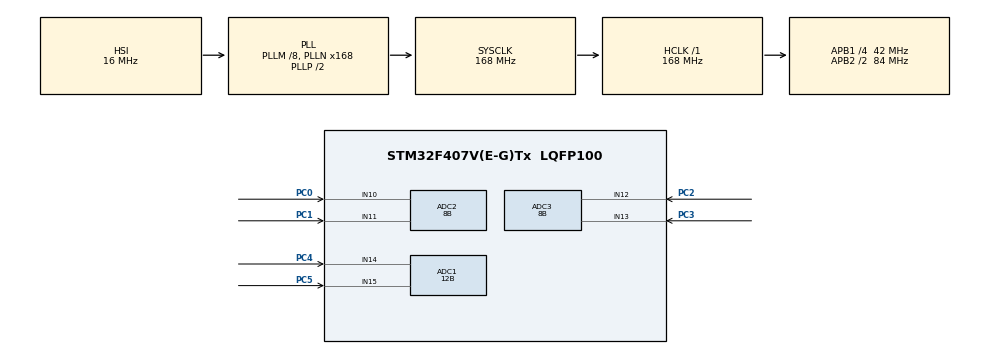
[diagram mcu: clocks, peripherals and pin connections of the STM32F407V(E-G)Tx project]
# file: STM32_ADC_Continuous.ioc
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ADC1.Channel-0\#ChannelRegularConversion=ADC_CHANNEL_15
ADC1.ClockPrescaler=ADC_CLOCK_SYNC_PCLK_DIV4
ADC1.ContinuousConvMode=ENABLE
ADC1.EnableAnalogWatchDog=false
ADC1.NbrOfConversion=1
ADC1.NbrOfConversionFlag=1
ADC1.Rank-0\#ChannelRegularConversion=1
ADC1.Resolution=ADC_RESOLUTION_12B
ADC1.SamplingTime-0\#ChannelRegularConversion=ADC_SAMPLETIME_3CYCLES
ADC1.master=1
ADC2.Channel-0\#ChannelRegularConversion=ADC_CHANNEL_11
ADC2.ContinuousConvMode=ENABLE
ADC2.NbrOfConversionFlag=1
ADC2.Rank-0\#ChannelRegularConversion=1
ADC2.Resolution=ADC_RESOLUTION_8B
ADC2.SamplingTime-0\#ChannelRegularConversion=ADC_SAMPLETIME_480CYCLES
ADC3.Channel-0\#ChannelRegularConversion=ADC_CHANNEL_13
ADC3.ContinuousConvMode=ENABLE
ADC3.NbrOfConversionFlag=1
ADC3.Rank-0\#ChannelRegularConversion=1
ADC3.Resolution=ADC_RESOLUTION_8B
ADC3.SamplingTime-0\#ChannelRegularConversion=ADC_SAMPLETIME_480CYCLES
Mcu.Family=STM32F4
Mcu.Name=STM32F407V(E-G)Tx
Mcu.Package=LQFP100
NVIC.PriorityGroup=NVIC_PRIORITYGROUP_4
PA13.Signal=SYS_JTMS-SWDIO
PA14.Signal=SYS_JTCK-SWCLK
PB3.Signal=SYS_JTDO-SWO
PC0.Signal=ADCx_IN10
PC1.Signal=ADCx_IN11
PC2.Signal=ADCx_IN12
PC3.Signal=ADCx_IN13
PC4.Signal=ADCx_IN14
PC5.Signal=ADCx_IN15
ProjectManager.HeapSize=0x200
ProjectManager.StackSize=0x400
ProjectManager.TargetToolchain=STM32CubeIDE
RCC.48MHZClocksFreq_Value=84000000
RCC.AHBFreq_Value=168000000
RCC.APB1CLKDivider=RCC_HCLK_DIV4
RCC.APB1Freq_Value=42000000
RCC.APB1TimFreq_Value=84000000
RCC.APB2CLKDivider=RCC_HCLK_DIV2
RCC.APB2Freq_Value=84000000
RCC.APB2TimFreq_Value=168000000
RCC.CortexFreq_Value=168000000
RCC.HCLKFreq_Value=168000000
RCC.HSE_VALUE=25000000
RCC.HSI_VALUE=16000000
RCC.LSE_VALUE=32768
RCC.PLLM=8
RCC.PLLN=168
RCC.SYSCLKFreq_VALUE=168000000
RCC.SYSCLKSource=RCC_SYSCLKSOURCE_PLLCLK
RCC.VCOOutputFreq_Value=336000000
SH.ADCx_IN10.0=ADC2_IN10,IN10
SH.ADCx_IN11.0=ADC2_IN11,IN11
SH.ADCx_IN12.0=ADC3_IN12,IN12
SH.ADCx_IN13.0=ADC3_IN13,IN13
SH.ADCx_IN14.0=ADC1_IN14,IN14
SH.ADCx_IN15.0=ADC1_IN15,IN15
board=custom

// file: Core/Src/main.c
/* USER CODE BEGIN Header */
/**
  ******************************************************************************
  * @file           : main.c
  * @brief          : Main program body
  ******************************************************************************
  * @attention
  *
  * <h2><center>&copy; Copyright (c) 2021 STMicroelectronics.
  * All rights reserved.</center></h2>
  *
  * This software component is licensed by ST under BSD 3-Clause license,
  * the "License"; You may not use this file except in compliance with the
  * License. You may obtain a copy of the License at:
  *                        opensource.org/licenses/BSD-3-Clause
  *
  ******************************************************************************
  */
/* USER CODE END Header */

#include "main.h"

ADC_HandleTypeDef hadc1;
ADC_HandleTypeDef hadc2;
ADC_HandleTypeDef hadc3;

void SystemClock_Config(void);
static void MX_GPIO_Init(void);
static void MX_ADC1_Init(void);
static void MX_ADC2_Init(void);
static void MX_ADC3_Init(void);

/* USER CODE BEGIN 0 */
uint32_t adc_val = 0;
/* USER CODE END 0 */

int main(void)
{

  /* MCU Configuration--------------------------------------------------------*/

  /* Reset of all peripherals, Initializes the Flash interface and the Systick. */
  HAL_Init();

  /* Configure the system clock */
  SystemClock_Config();

  /* Initialize all configured peripherals */
  MX_GPIO_Init();
  MX_ADC1_Init();
  MX_ADC2_Init();
  MX_ADC3_Init();
  /* USER CODE BEGIN 2 */
  //ADC1 - PC4 (IN14), PC5 (IN15)
  //ADC2 - PC0 (IN10), PC1 (IN11)
  //ADC3 - PC2 (IN12), PC3 (IN13)
  //HAL_ADC_Start(&hadc1);
  //HAL_ADC_Start(&hadc2);
  HAL_ADC_Start(&hadc3);
  /* USER CODE END 2 */

  /* Infinite loop */
  while (1)
  {

    /* USER CODE BEGIN 3 */
	  //adc_val = HAL_ADC_GetValue(&hadc1);
	  //adc_val = HAL_ADC_GetValue(&hadc2);
	  adc_val = HAL_ADC_GetValue(&hadc3);
	  //HAL_Delay(50);
  }
  /* USER CODE END 3 */
}

void SystemClock_Config(void)
{
  RCC_OscInitTypeDef RCC_OscInitStruct = {0};
  RCC_ClkInitTypeDef RCC_ClkInitStruct = {0};

  /** Configure the main internal regulator output voltage
  */
  __HAL_RCC_PWR_CLK_ENABLE();
  __HAL_PWR_VOLTAGESCALING_CONFIG(PWR_REGULATOR_VOLTAGE_SCALE1);
  /** Initializes the CPU, AHB and APB busses clocks
  */
  RCC_OscInitStruct.OscillatorType = RCC_OSCILLATORTYPE_HSI;
  RCC_OscInitStruct.HSIState = RCC_HSI_ON;
  RCC_OscInitStruct.HSICalibrationValue = RCC_HSICALIBRATION_DEFAULT;
  RCC_OscInitStruct.PLL.PLLState = RCC_PLL_ON;
  RCC_OscInitStruct.PLL.PLLSource = RCC_PLLSOURCE_HSI;
  RCC_OscInitStruct.PLL.PLLM = 8;
  RCC_OscInitStruct.PLL.PLLN = 168;
  RCC_OscInitStruct.PLL.PLLP = RCC_PLLP_DIV2;
  RCC_OscInitStruct.PLL.PLLQ = 4;
  if (HAL_RCC_OscConfig(&RCC_OscInitStruct) != HAL_OK)
  {
    Error_Handler();
  }
  /** Initializes the CPU, AHB and APB busses clocks
  */
  RCC_ClkInitStruct.ClockType = RCC_CLOCKTYPE_HCLK|RCC_CLOCKTYPE_SYSCLK
                              |RCC_CLOCKTYPE_PCLK1|RCC_CLOCKTYPE_PCLK2;
  RCC_ClkInitStruct.SYSCLKSource = RCC_SYSCLKSOURCE_PLLCLK;
  RCC_ClkInitStruct.AHBCLKDivider = RCC_SYSCLK_DIV1;
  RCC_ClkInitStruct.APB1CLKDivider = RCC_HCLK_DIV4;
  RCC_ClkInitStruct.APB2CLKDivider = RCC_HCLK_DIV2;

  if (HAL_RCC_ClockConfig(&RCC_ClkInitStruct, FLASH_LATENCY_5) != HAL_OK)
  {
    Error_Handler();
  }
}

static void MX_ADC1_Init(void)
{

  ADC_ChannelConfTypeDef sConfig = {0};

  /** Configure the global features of the ADC (Clock, Resolution, Data Alignment and number of conversion)
  */
  hadc1.Instance = ADC1;
  hadc1.Init.ClockPrescaler = ADC_CLOCK_SYNC_PCLK_DIV4;
  hadc1.Init.Resolution = ADC_RESOLUTION_12B;
  hadc1.Init.ScanConvMode = DISABLE;
  hadc1.Init.ContinuousConvMode = ENABLE;
  hadc1.Init.DiscontinuousConvMode = DISABLE;
  hadc1.Init.ExternalTrigConvEdge = ADC_EXTERNALTRIGCONVEDGE_NONE;
  hadc1.Init.ExternalTrigConv = ADC_SOFTWARE_START;
  hadc1.Init.DataAlign = ADC_DATAALIGN_RIGHT;
  hadc1.Init.NbrOfConversion = 1;
  hadc1.Init.DMAContinuousRequests = DISABLE;
  hadc1.Init.EOCSelection = ADC_EOC_SINGLE_CONV;
  if (HAL_ADC_Init(&hadc1) != HAL_OK)
  {
    Error_Handler();
  }
  /** Configure for the selected ADC regular channel its corresponding rank in the sequencer and its sample time.
  */
  sConfig.Channel = ADC_CHANNEL_15;
  sConfig.Rank = 1;
  sConfig.SamplingTime = ADC_SAMPLETIME_3CYCLES;
  if (HAL_ADC_ConfigChannel(&hadc1, &sConfig) != HAL_OK)
  {
    Error_Handler();
  }

}

static void MX_ADC2_Init(void)
{

  ADC_ChannelConfTypeDef sConfig = {0};

  /** Configure the global features of the ADC (Clock, Resolution, Data Alignment and number of conversion)
  */
  hadc2.Instance = ADC2;
  hadc2.Init.ClockPrescaler = ADC_CLOCK_SYNC_PCLK_DIV4;
  hadc2.Init.Resolution = ADC_RESOLUTION_8B;
  hadc2.Init.ScanConvMode = DISABLE;
  hadc2.Init.ContinuousConvMode = ENABLE;
  hadc2.Init.DiscontinuousConvMode = DISABLE;
  hadc2.Init.ExternalTrigConvEdge = ADC_EXTERNALTRIGCONVEDGE_NONE;
  hadc2.Init.ExternalTrigConv = ADC_SOFTWARE_START;
  hadc2.Init.DataAlign = ADC_DATAALIGN_RIGHT;
  hadc2.Init.NbrOfConversion = 1;
  hadc2.Init.DMAContinuousRequests = DISABLE;
  hadc2.Init.EOCSelection = ADC_EOC_SINGLE_CONV;
  if (HAL_ADC_Init(&hadc2) != HAL_OK)
  {
    Error_Handler();
  }
  /** Configure for the selected ADC regular channel its corresponding rank in the sequencer and its sample time.
  */
  sConfig.Channel = ADC_CHANNEL_11;
  sConfig.Rank = 1;
  sConfig.SamplingTime = ADC_SAMPLETIME_480CYCLES;
  if (HAL_ADC_ConfigChannel(&hadc2, &sConfig) != HAL_OK)
  {
    Error_Handler();
  }

}

static void MX_ADC3_Init(void)
{

  ADC_ChannelConfTypeDef sConfig = {0};

  /** Configure the global features of the ADC (Clock, Resolution, Data Alignment and number of conversion)
  */
  hadc3.Instance = ADC3;
  hadc3.Init.ClockPrescaler = ADC_CLOCK_SYNC_PCLK_DIV4;
  hadc3.Init.Resolution = ADC_RESOLUTION_8B;
  hadc3.Init.ScanConvMode = DISABLE;
  hadc3.Init.ContinuousConvMode = ENABLE;
  hadc3.Init.DiscontinuousConvMode = DISABLE;
  hadc3.Init.ExternalTrigConvEdge = ADC_EXTERNALTRIGCONVEDGE_NONE;
  hadc3.Init.ExternalTrigConv = ADC_SOFTWARE_START;
  hadc3.Init.DataAlign = ADC_DATAALIGN_RIGHT;
  hadc3.Init.NbrOfConversion = 1;
  hadc3.Init.DMAContinuousRequests = DISABLE;
  hadc3.Init.EOCSelection = ADC_EOC_SINGLE_CONV;
  if (HAL_ADC_Init(&hadc3) != HAL_OK)
  {
    Error_Handler();
  }
  /** Configure for the selected ADC regular channel its corresponding rank in the sequencer and its sample time.
  */
  sConfig.Channel = ADC_CHANNEL_13;
  sConfig.Rank = 1;
  sConfig.SamplingTime = ADC_SAMPLETIME_480CYCLES;
  if (HAL_ADC_ConfigChannel(&hadc3, &sConfig) != HAL_OK)
  {
    Error_Handler();
  }

}

static void MX_GPIO_Init(void)
{

  /* GPIO Ports Clock Enable */
  __HAL_RCC_GPIOC_CLK_ENABLE();
  __HAL_RCC_GPIOA_CLK_ENABLE();
  __HAL_RCC_GPIOB_CLK_ENABLE();

}

void Error_Handler(void)
{
}

/************************ (C) COPYRIGHT STMicroelectronics *****END OF FILE****/
